# STM32H743x register map
File version: 1.0
CPU: CM7 r0p1, little endian, MPU, FPU, 4 interrupt priority bits
Registers are 32-bit, read-write, reset 0x0 unless marked. A register's access mark holds for its fields unless they carry their own. Offsets are from the block's base; [hi:lo] are bit positions; {n}, {i} and the like mark numbered series.

## ADC3_Common — Analog-to-Digital Converter
Base 0x58026300
Same registers: ADC12_Common 0x40022300
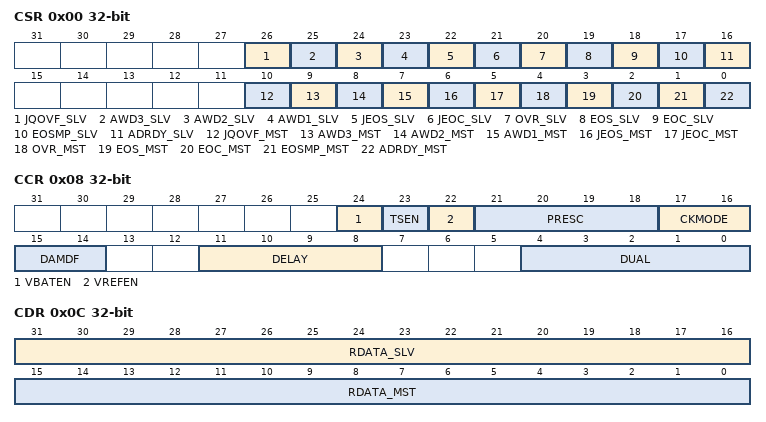
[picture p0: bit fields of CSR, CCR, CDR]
0x00 CSR ro — ADC Common status register
  [26] JQOVF_SLV — Injected Context Queue Overflow flag of the slave ADC
  [25] AWD3_SLV — Analog watchdog 3 flag of the slave ADC
  [24] AWD2_SLV — Analog watchdog 2 flag of the slave ADC
  [23] AWD1_SLV — Analog watchdog 1 flag of the slave ADC
  [22] JEOS_SLV — End of injected sequence flag of the slave ADC
  [21] JEOC_SLV — End of injected conversion flag of the slave ADC
  [20] OVR_SLV — Overrun flag of the slave ADC
  [19] EOS_SLV — End of regular sequence flag of the slave ADC
  [18] EOC_SLV — End of regular conversion of the slave ADC
  [17] EOSMP_SLV — End of Sampling phase flag of the slave ADC
  [16] ADRDY_SLV — Slave ADC ready
  [10] JQOVF_MST — Injected Context Queue Overflow flag of the master ADC
  [9] AWD3_MST — Analog watchdog 3 flag of the master ADC
  [8] AWD2_MST — Analog watchdog 2 flag of the master ADC
  [7] AWD1_MST — Analog watchdog 1 flag of the master ADC
  [6] JEOS_MST — End of injected sequence flag of the master ADC
  [5] JEOC_MST — End of injected conversion flag of the master ADC
  [4] OVR_MST — Overrun flag of the master ADC
  [3] EOS_MST — End of regular sequence flag of the master ADC
  [2] EOC_MST — End of regular conversion of the master ADC
  [1] EOSMP_MST — End of Sampling phase flag of the master ADC
  [0] ADRDY_MST — Master ADC ready
0x08 CCR — ADC common control register
  [24] VBATEN — VBAT enable
  [23] TSEN — Temperature sensor enable
  [22] VREFEN — VREFINT enable
  [21:18] PRESC — ADC prescaler
  [17:16] CKMODE — ADC clock mode
  [15:14] DAMDF — Dual ADC Mode Data Format
  [11:8] DELAY — Delay between 2 sampling phases
  [4:0] DUAL — Dual ADC mode selection
0x0C CDR ro — ADC common regular data register for dual and triple modes
  [31:16] RDATA_SLV — Regular data of the slave ADC
  [15:0] RDATA_MST — Regular data of the master ADC
0x10 CDR2 ro — ADC x common regular data register for 32-bit dual mode
  [31:0] RDATA_ALT — Regular data of the master/slave alternated ADCs

## CRC — Cyclic redundancy check calculation unit
Base 0x58024C00
0x00 DR reset 0xFFFFFFFF — Data register
  [31:0] DR — Data register bits
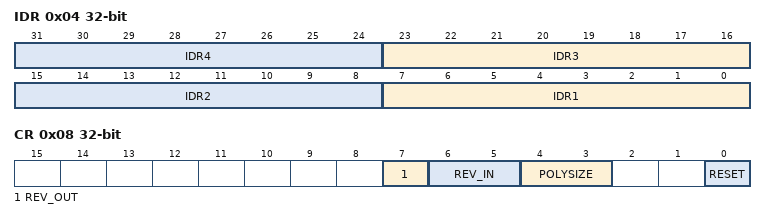
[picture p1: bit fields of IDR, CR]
0x04 IDR — Independent data register
  [8n-1:8n-8] IDR{n} (n=1..4) — General-purpose 8-bit data register bits
0x08 CR access per field — Control register
  [7] REV_OUT rw — Reverse output data
  [6:5] REV_IN rw — Reverse input data
  [4:3] POLYSIZE rw — Polynomial size
  [0] RESET wo — RESET bit
0x10 INIT reset 0xFFFFFFFF — Initial CRC value
  [31:0] CRC_INIT — Programmable initial CRC value
0x14 POL reset 0x4C11DB7 — polynomial
  [31:0] POL — Programmable polynomial

## LPTIM1 — Low power timer
Base 0x40002400
Same registers: LPTIM2 0x58002400
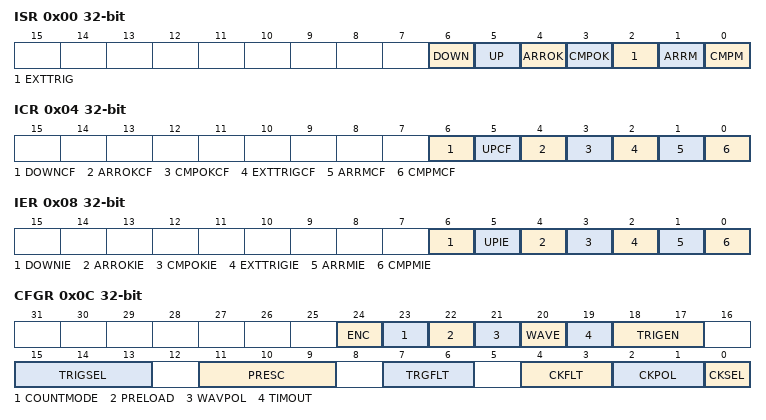
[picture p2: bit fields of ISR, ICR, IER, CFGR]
0x00 ISR ro — Interrupt and Status Register
  [6] DOWN — Counter direction change up to down
  [5] UP — Counter direction change down to up
  [4] ARROK — Autoreload register update OK
  [3] CMPOK — Compare register update OK
  [2] EXTTRIG — External trigger edge event
  [1] ARRM — Autoreload match
  [0] CMPM — Compare match
0x04 ICR wo — Interrupt Clear Register
  [6] DOWNCF — Direction change to down Clear Flag
  [5] UPCF — Direction change to UP Clear Flag
  [4] ARROKCF — Autoreload register update OK Clear Flag
  [3] CMPOKCF — Compare register update OK Clear Flag
  [2] EXTTRIGCF — External trigger valid edge Clear Flag
  [1] ARRMCF — Autoreload match Clear Flag
  [0] CMPMCF — compare match Clear Flag
0x08 IER — Interrupt Enable Register
  [6] DOWNIE — Direction change to down Interrupt Enable
  [5] UPIE — Direction change to UP Interrupt Enable
  [4] ARROKIE — Autoreload register update OK Interrupt Enable
  [3] CMPOKIE — Compare register update OK Interrupt Enable
  [2] EXTTRIGIE — External trigger valid edge Interrupt Enable
  [1] ARRMIE — Autoreload match Interrupt Enable
  [0] CMPMIE — Compare match Interrupt Enable
0x0C CFGR — Configuration Register
  [24] ENC — Encoder mode enable
  [23] COUNTMODE — counter mode enabled
  [22] PRELOAD — Registers update mode
  [21] WAVPOL — Waveform shape polarity
  [20] WAVE — Waveform shape
  [19] TIMOUT — Timeout enable
  [18:17] TRIGEN — Trigger enable and polarity
  [15:13] TRIGSEL — Trigger selector
  [11:9] PRESC — Clock prescaler
  [7:6] TRGFLT — Configurable digital filter for trigger
  [4:3] CKFLT — Configurable digital filter for external clock
  [2:1] CKPOL — Clock Polarity
  [0] CKSEL — Clock selector
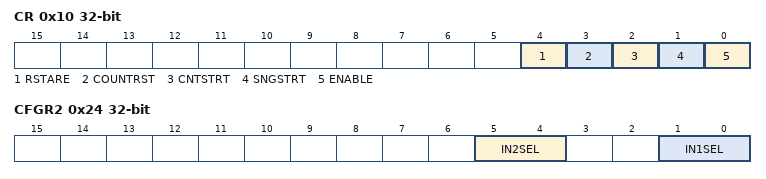
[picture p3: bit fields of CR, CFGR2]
0x10 CR — Control Register
  [4] RSTARE — Reset after read enable
  [3] COUNTRST — Counter reset
  [2] CNTSTRT — Timer start in continuous mode
  [1] SNGSTRT — LPTIM start in single mode
  [0] ENABLE — LPTIM Enable
0x14 CMP — Compare Register
  [15:0] CMP — Compare value
0x18 ARR reset 0x1 — Autoreload Register
  [15:0] ARR — Auto reload value
0x1C CNT ro — Counter Register
  [15:0] CNT — Counter value
0x24 CFGR2 — LPTIM configuration register 2
  [5:4] IN2SEL — LPTIM Input 2 selection
  [1:0] IN1SEL — LPTIM Input 1 selection

## LPTIM3 — Low power timer
Base 0x58002800
Same registers: LPTIM4 0x58002C00, LPTIM5 0x58003000
Registers as LPTIM1; these are added or differ:
0x24 CFGR2 — LPTIM configuration register 2
  [1:0] IN1SEL — LPTIM Input 1 selection
